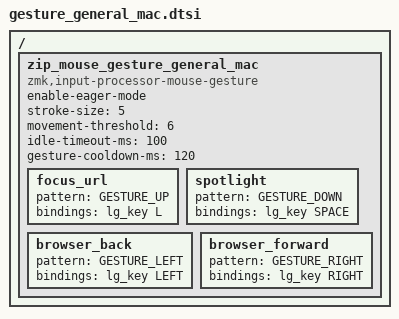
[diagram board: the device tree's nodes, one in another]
/ {
  zip_mouse_gesture_general_mac: zip_mouse_gesture_general_mac {
    compatible = "zmk,input-processor-mouse-gesture";
    #input-processor-cells = <0>;
    enable-eager-mode;
    stroke-size = <5>;
    movement-threshold = <6>;
    idle-timeout-ms = <100>;
    gesture-cooldown-ms = <120>;

    focus_url       { pattern = <GESTURE_UP>;    bindings = <&lg_key L>;     };  // URLバー選択
    spotlight       { pattern = <GESTURE_DOWN>;  bindings = <&lg_key SPACE>; };  // Spotlight / Raycast
    browser_back    { pattern = <GESTURE_LEFT>;  bindings = <&lg_key LEFT>;  };  // ブラウザ戻る
    browser_forward { pattern = <GESTURE_RIGHT>; bindings = <&lg_key RIGHT>; };  // ブラウザ進む
  };
};
